# STM32F407 register map
File version: 1.2
CPU: CM4 r1p0, little endian, no MPU, no FPU, 3 interrupt priority bits
Registers are 32-bit, read-write, reset 0x0 unless marked. A register's access mark holds for its fields unless they carry their own. Offsets are from the block's base; [hi:lo] are bit positions; {n}, {i} and the like mark numbered series.

## SCB — System control block
Base 0xE000ED00
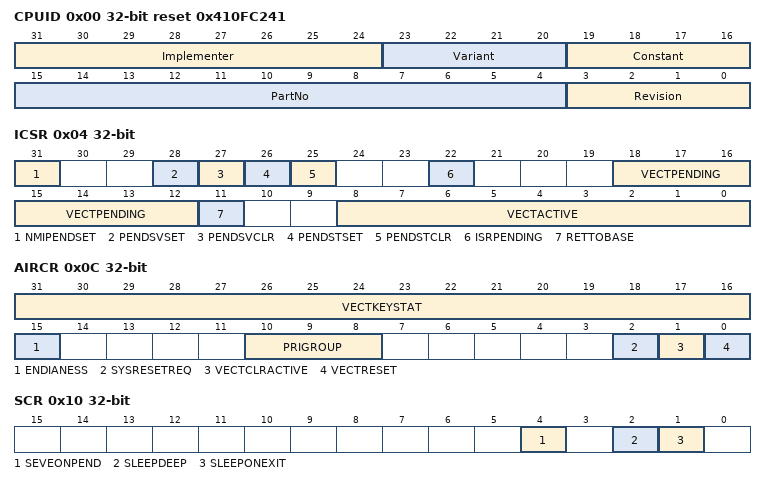
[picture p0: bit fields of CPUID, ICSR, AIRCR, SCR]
0x00 CPUID ro reset 0x410FC241 — CPUID base register
  [31:24] Implementer — Implementer code
  [23:20] Variant — Variant number
  [19:16] Constant — Reads as 0xF
  [15:4] PartNo — Part number of the processor
  [3:0] Revision — Revision number
0x04 ICSR — Interrupt control and state register
  [31] NMIPENDSET — NMI set-pending bit.
  [28] PENDSVSET — PendSV set-pending bit
  [27] PENDSVCLR — PendSV clear-pending bit
  [26] PENDSTSET — SysTick exception set-pending bit
  [25] PENDSTCLR — SysTick exception clear-pending bit
  [22] ISRPENDING — Interrupt pending flag
  [18:12] VECTPENDING — Pending vector
  [11] RETTOBASE — Return to base level
  [8:0] VECTACTIVE — Active vector
0x08 VTOR — Vector table offset register
  [29:9] TBLOFF — Vector table base offset field
0x0C AIRCR — Application interrupt and reset control register
  [31:16] VECTKEYSTAT — Register key
  [15] ENDIANESS
  [10:8] PRIGROUP
  [2] SYSRESETREQ
  [1] VECTCLRACTIVE
  [0] VECTRESET
0x10 SCR — System control register
  [4] SEVEONPEND — Send Event on Pending bit
  [2] SLEEPDEEP
  [1] SLEEPONEXIT
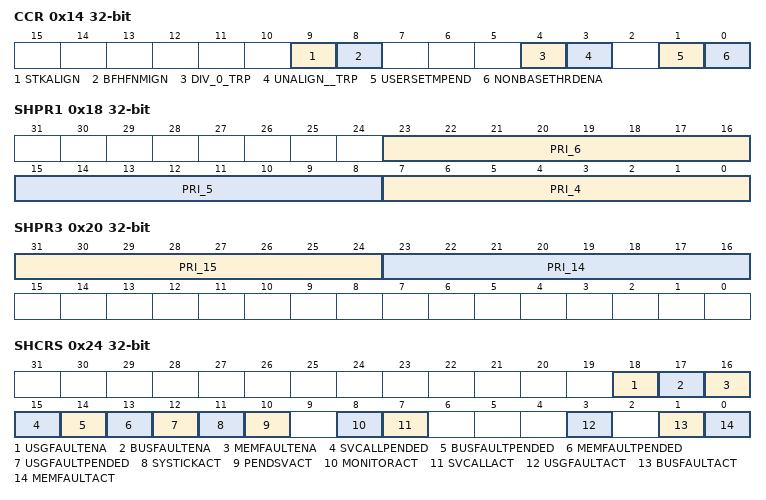
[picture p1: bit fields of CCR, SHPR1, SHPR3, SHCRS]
0x14 CCR — Configuration and control register
  [9] STKALIGN
  [8] BFHFNMIGN
  [4] DIV_0_TRP
  [3] UNALIGN__TRP
  [1] USERSETMPEND
  [0] NONBASETHRDENA — Configures how the processor enters Thread mode
0x18 SHPR1 — System handler priority registers
  [23:16] PRI_6 — Priority of system handler 6
  [15:8] PRI_5 — Priority of system handler 5
  [7:0] PRI_4 — Priority of system handler 4
0x1C SHPR2 — System handler priority registers
  [31:24] PRI_11 — Priority of system handler 11
0x20 SHPR3 — System handler priority registers
  [31:24] PRI_15 — Priority of system handler 15
  [23:16] PRI_14 — Priority of system handler 14
0x24 SHCRS — System handler control and state register
  [18] USGFAULTENA — Usage fault enable bit
  [17] BUSFAULTENA — Bus fault enable bit
  [16] MEMFAULTENA — Memory management fault enable bit
  [15] SVCALLPENDED — SVC call pending bit
  [14] BUSFAULTPENDED — Bus fault exception pending bit
  [13] MEMFAULTPENDED — Memory management fault exception pending bit
  [12] USGFAULTPENDED — Usage fault exception pending bit
  [11] SYSTICKACT — SysTick exception active bit
  [10] PENDSVACT — PendSV exception active bit
  [8] MONITORACT — Debug monitor active bit
  [7] SVCALLACT — SVC call active bit
  [3] USGFAULTACT — Usage fault exception active bit
  [1] BUSFAULTACT — Bus fault exception active bit
  [0] MEMFAULTACT — Memory management fault exception active bit
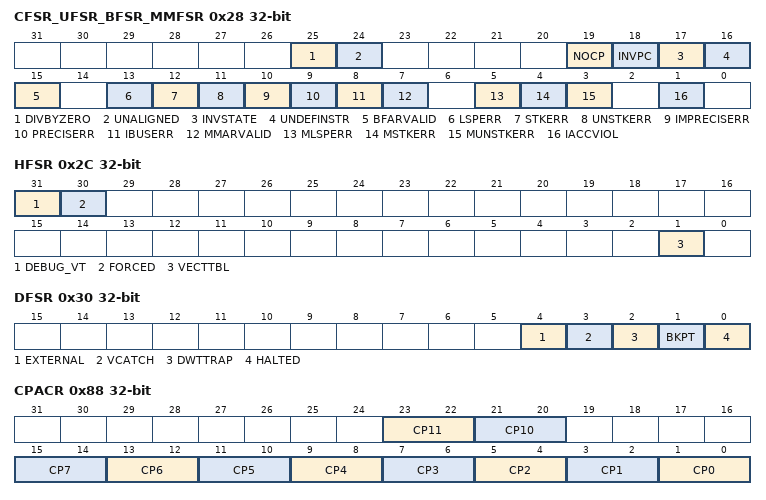
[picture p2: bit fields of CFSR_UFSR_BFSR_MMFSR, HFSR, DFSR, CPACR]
0x28 CFSR_UFSR_BFSR_MMFSR — Configurable fault status register
  [25] DIVBYZERO — Divide by zero usage fault
  [24] UNALIGNED — Unaligned access usage fault
  [19] NOCP — No coprocessor usage fault.
  [18] INVPC — Invalid PC load usage fault
  [17] INVSTATE — Invalid state usage fault
  [16] UNDEFINSTR — Undefined instruction usage fault
  [15] BFARVALID — Bus Fault Address Register (BFAR) valid flag
  [13] LSPERR — Bus fault on floating-point lazy state preservation
  [12] STKERR — Bus fault on stacking for exception entry
  [11] UNSTKERR — Bus fault on unstacking for a return from exception
  [10] IMPRECISERR — Imprecise data bus error
  [9] PRECISERR — Precise data bus error
  [8] IBUSERR — Instruction bus error
  [7] MMARVALID — Memory Management Fault Address Register (MMAR) valid flag
  [5] MLSPERR
  [4] MSTKERR — Memory manager fault on stacking for exception entry.
  [3] MUNSTKERR — Memory manager fault on unstacking for a return from exception
  [1] IACCVIOL — Instruction access violation flag
0x2C HFSR — Hard fault status register
  [31] DEBUG_VT — Reserved for Debug use
  [30] FORCED — Forced hard fault
  [1] VECTTBL — Vector table hard fault
0x30 DFSR — Debug fault status register
  [4] EXTERNAL
  [3] VCATCH — Vector Catch
  [2] DWTTRAP — Debug Event Trap
  [1] BKPT — Breakpoint
  [0] HALTED
0x34 MMFAR — Memory management fault address register
  [31:0] MMFAR — Memory management fault address
0x38 BFAR — Bus fault address register
  [31:0] BFAR — Bus fault address
0x3C AFSR — Auxiliary fault status register
  [31:0] IMPDEF — Implementation defined
0x88 CPACR — Coprocessor Access Control Register
  [23:22] CP11 — Coprocessor 0
  [21:20] CP10 — Coprocessor 0
  [2n+1:2n] CP{n} (n=0..7) — Coprocessor {n}

## SIG — Software Interrupt Generation
Base 0xE000EF00
0x00 STIR wo — Provides a mechanism for software to generate an interrupt
  [8:0] INTID — Indicates the interrupt to be triggered

## DBG — Debug support
Base 0xE0042000
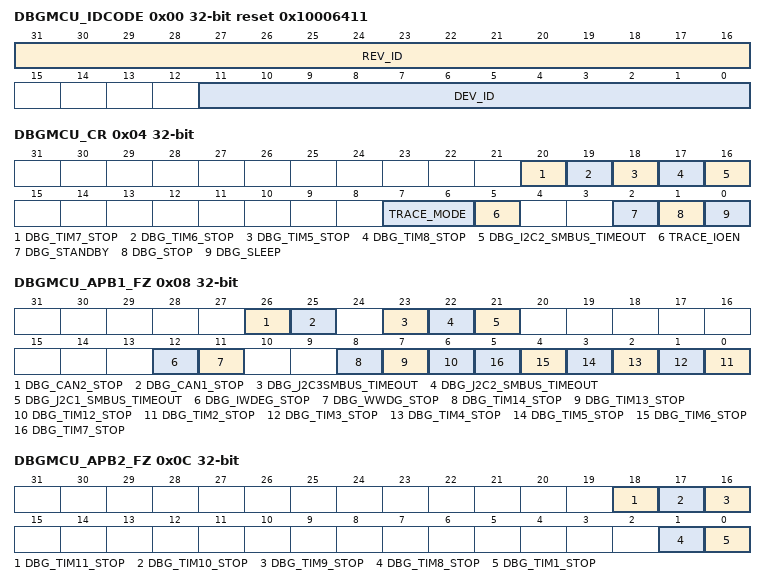
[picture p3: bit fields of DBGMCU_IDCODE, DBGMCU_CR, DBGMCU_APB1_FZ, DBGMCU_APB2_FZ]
0x00 DBGMCU_IDCODE ro reset 0x10006411 — IDCODE
  [31:16] REV_ID, [11:0] DEV_ID
0x04 DBGMCU_CR — Control Register
  [20] DBG_TIM7_STOP, [19] DBG_TIM6_STOP, [18] DBG_TIM5_STOP, [17] DBG_TIM8_STOP, [16] DBG_I2C2_SMBUS_TIMEOUT, [7:6] TRACE_MODE, [5] TRACE_IOEN, [2] DBG_STANDBY, [1] DBG_STOP, [0] DBG_SLEEP
0x08 DBGMCU_APB1_FZ — Debug MCU APB1 Freeze register
  [26] DBG_CAN2_STOP, [25] DBG_CAN1_STOP, [23] DBG_J2C3SMBUS_TIMEOUT, [22] DBG_J2C2_SMBUS_TIMEOUT, [21] DBG_J2C1_SMBUS_TIMEOUT, [12] DBG_IWDEG_STOP, [11] DBG_WWDG_STOP, [8] DBG_TIM14_STOP, [7] DBG_TIM13_STOP, [6] DBG_TIM12_STOP, [n-2] DBG_TIM{n}_STOP (n=2..7)
0x0C DBGMCU_APB2_FZ — Debug MCU APB2 Freeze registe
  [18] DBG_TIM11_STOP — TIM11 counter stopped when core is halted
  [17] DBG_TIM10_STOP — TIM10 counter stopped when core is halted
  [16] DBG_TIM9_STOP — TIM9 counter stopped when core is halted
  [1] DBG_TIM8_STOP — TIM8 counter stopped when core is halted
  [0] DBG_TIM1_STOP — TIM1 counter stopped when core is halted
